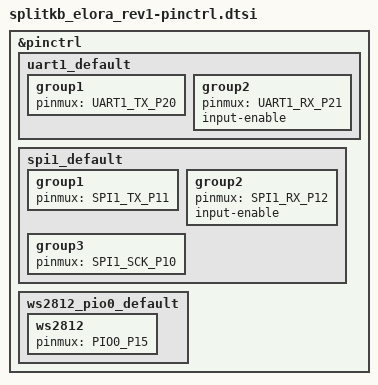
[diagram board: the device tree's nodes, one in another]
/*
 * Copyright (c) 2026 The ZMK Contributors
 *
 * SPDX-License-Identifier: MIT
 */

#include <dt-bindings/pinctrl/rpi-pico-rp2040-pinctrl.h>

&pinctrl {
    uart1_default: uart1_default {
        group1 {
            pinmux = <UART1_TX_P20>;
        };
        group2 {
            pinmux = <UART1_RX_P21>;
            input-enable;
        };
    };

    spi1_default: spi1_default {
        group1 {
            pinmux = <SPI1_TX_P11>;
        };
        group2 {
            pinmux = <SPI1_RX_P12>;
            input-enable;
        };
        group3 {
            pinmux = <SPI1_SCK_P10>;
        };
    };

    ws2812_pio0_default: ws2812_pio0_default {
        ws2812 {
            pinmux = <PIO0_P15>;
        };
    };
};
